VERSION ""

NS_ :

BS_:

BU_: Device Host

BO_ 2381865214 DegradedModeMsg: 8 Vector__XXX
 SG_ SteeringDegradedModeDemand : 2|2@1+ (1,0) [0|3] "" Vector__XXX
 SG_ BrakingDegradedModeDemand : 0|2@1+ (1,0) [0|3] "" Vector__XXX

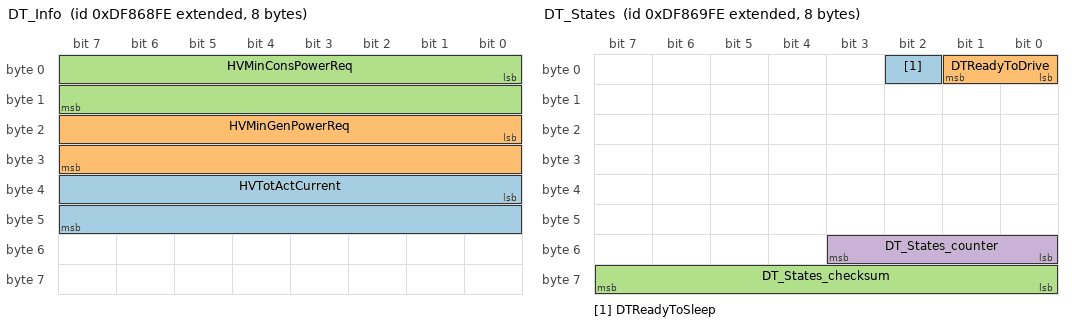
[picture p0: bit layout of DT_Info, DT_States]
BO_ 2381867262 DT_Info: 8 Vector__XXX
 SG_ HVTotActCurrent : 32|16@1+ (0.05,0) [0|3276.75] "A" Vector__XXX
 SG_ HVMinGenPowerReq : 16|16@1+ (0.1,0) [0|6553.5] "kW" Vector__XXX
 SG_ HVMinConsPowerReq : 0|16@1+ (0.1,0) [0|6553.5] "kW" Vector__XXX

BO_ 2381867518 DT_States: 8 Vector__XXX
 SG_ DTReadyToSleep : 2|1@1+ (1,0) [0|1] "" Vector__XXX
 SG_ DTReadyToDrive : 0|2@1+ (1,0) [0|3] "" Vector__XXX
 SG_ DT_States_checksum : 56|8@1+ (1,0) [0|255] "" Vector__XXX
 SG_ DT_States_counter : 48|4@1+ (1,0) [0|15] "" Vector__XXX

CM_ "Arrival Drivetrain Controller Database.
$DBC storage: //depot/auto/dbc/Software_Modules/Drivetrain_Controller/ArrivalDTC/ $
$Change: 0 $
$DateTime: 2020/11/02 14:30:00 $
$Revision: #1 $
$Author: lyamin@arrival.com $
";
CM_ SG_ 2381865214 SteeringDegradedModeDemand "Drivetrain readiness flag";
CM_ SG_ 2381865214 BrakingDegradedModeDemand "Drivetrain readiness flag";
CM_ SG_ 2381867262 HVTotActCurrent "Drivetrain readiness flag";
CM_ SG_ 2381867262 HVMinGenPowerReq "Drivetrain readiness flag";
CM_ SG_ 2381867262 HVMinConsPowerReq "Drivetrain readiness flag";
CM_ BO_ 2381867518 "Message with general information about current Drivetrain Controller state";
CM_ SG_ 2381867518 DTReadyToSleep "Drivetrain readiness flag";
CM_ SG_ 2381867518 DTReadyToDrive "Drivetrain readiness flag";
BA_DEF_  "BusType" STRING ;
BA_DEF_  "DBName" STRING ;
BA_DEF_  "DatabaseVersion" STRING ;
BA_DEF_ BO_  "GenMsgCycleTime" INT 0 3600000;
BA_DEF_ BO_  "GenMsgILSupport" ENUM  "No","Yes";
BA_DEF_ BO_  "GenMsgRequestable" INT 0 1;
BA_DEF_ BO_  "GenMsgSendType" ENUM  "cyclic","NotUsed","NotUsed","NotUsed","NotUsed","NotUsed","NotUsed","IfActive","noMsgSendType";
BA_DEF_ SG_  "GenSigEVName" STRING ;
BA_DEF_ SG_  "GenSigILSupport" ENUM  "No","Yes";
BA_DEF_ SG_  "GenSigSendType" ENUM  "Cyclic","OnWrite","OnWriteWithRepetition","OnChange","OnChangeWithRepetition","IfActive","IfActiveWithRepetition","NoSigSendType";
BA_DEF_ SG_  "GenSigStartValue" INT 0 2147483647;
BA_DEF_ BU_  "NmStationAddress" INT 0 255;
BA_DEF_  "ProtocolType" STRING ;
BA_DEF_  "SAE_J1939_21_SpecVersion" STRING ;
BA_DEF_  "SAE_J1939_71_SpecVersion" STRING ;
BA_DEF_  "SAE_J1939_73_SpecVersion" STRING ;
BA_DEF_  "SAE_J1939_75_SpecVersion" STRING ;
BA_DEF_  "SAE_J1939_81_SpecVersion" STRING ;
BA_DEF_  "SAE_J1939_DA_SpecVersion" STRING ;
BA_DEF_ BO_  "SendOnChange" ENUM  "No","Yes";
BA_DEF_ BO_  "Producer" STRING ;
BA_DEF_ SG_  "SigType" ENUM  "Default","Range","RangeSigned","ASCII","Discrete","Control","ReferencePGN","DTC","StringDelimiter","StringLength","StringLengthControl","MessageCounter","MessageChecksum";
BA_DEF_ BO_  "VFrameFormat" ENUM  "StandardCAN","ExtendedCAN","reserved","J1939PG","reserved","reserved","reserved","reserved","reserved","reserved","reserved","reserved","reserved","reserved","StandardCAN_FD","ExtendedCAN_FD";
BA_DEF_DEF_  "BusType" "";
BA_DEF_DEF_ "Producer" "DTS" ;
BA_DEF_DEF_  "DBName" "";
BA_DEF_DEF_  "DatabaseVersion" "";
BA_DEF_DEF_  "GenMsgCycleTime" 0;
BA_DEF_DEF_  "GenMsgILSupport" "Yes";
BA_DEF_DEF_  "GenMsgRequestable" 1;
BA_DEF_DEF_  "GenMsgSendType" "noMsgSendType";
BA_DEF_DEF_  "GenSigEVName" "Env@Nodename_@Signame";
BA_DEF_DEF_  "GenSigILSupport" "Yes";
BA_DEF_DEF_  "GenSigSendType" "NoSigSendType";
BA_DEF_DEF_  "GenSigStartValue" 0;
BA_DEF_DEF_  "NmStationAddress" 254;
BA_DEF_DEF_  "ProtocolType" "";
BA_DEF_DEF_  "SAE_J1939_21_SpecVersion" "";
BA_DEF_DEF_  "SAE_J1939_71_SpecVersion" "";
BA_DEF_DEF_  "SAE_J1939_73_SpecVersion" "";
BA_DEF_DEF_  "SAE_J1939_75_SpecVersion" "";
BA_DEF_DEF_  "SAE_J1939_81_SpecVersion" "";
BA_DEF_DEF_  "SAE_J1939_DA_SpecVersion" "";
BA_DEF_DEF_  "SendOnChange" "No";
BA_DEF_DEF_  "SigType" "Default";
BA_DEF_DEF_  "VFrameFormat" "J1939PG";
BA_ "BusType" "CAN";
BA_ "DatabaseVersion" "1.0";
BA_ "ProtocolType" "J1939";
BA_ "SAE_J1939_21_SpecVersion" "2006-10";
BA_ "SAE_J1939_71_SpecVersion" "2012-10";
BA_ "SAE_J1939_73_SpecVersion" "2012-10";
BA_ "SAE_J1939_75_SpecVersion" "2012-05";
BA_ "SAE_J1939_81_SpecVersion" "2012-05";
BA_ "SAE_J1939_DA_SpecVersion" "2015-01";
BA_ "DBName" "ArrivalDTC";
BA_ "GenMsgSendType" BO_ 2381865214 0;
BA_ "GenMsgCycleTime" BO_ 2381865214 500;
BA_ "GenMsgCycleTime" BO_ 2381867262 100;
BA_ "GenMsgSendType" BO_ 2381867262 0;
BA_ "GenMsgSendType" BO_ 2381867518 0;
BA_ "GenMsgCycleTime" BO_ 2381867518 100;
BA_ "SendOnChange" BO_ 2381867518 1;
BA_ "GenSigStartValue" SG_ 2381867518 DTReadyToDrive 3;
BA_ "GenSigSendType" SG_ 2381867518 DT_States_checksum 0;
BA_ "SigType" SG_ 2381867518 DT_States_checksum 12;
BA_ "SigType" SG_ 2381867518 DT_States_counter 11;
BA_ "GenSigSendType" SG_ 2381867518 DT_States_counter 0;
VAL_ 2381865214 SteeringDegradedModeDemand 3 "NA" 2 "Reserved" 0 "Off" 1 "On" ;
VAL_ 2381865214 BrakingDegradedModeDemand 3 "NA" 2 "Reserved" 0 "Off" 1 "On" ;
VAL_ 2381867518 DTReadyToDrive 3 "NA" 2 "Error" 0 "Not Ready" 1 "Ready" ;
